AUTOSAR XML (schema 4-0-3)
package /CalibrationComponents
  parameter sw component type VSDR: data-type-mapping=[VSDR_CodeDataTypeMappingsSet, WorkingDataTypeMappingsSet]
    provide port VSDR_Pport: provided-interface=VSDR_if
      provided-com-specs:
        init-value=VSDR_Pport_KaVSDR_I_OvrdValue_HallSensorCalOffSet:[0, 0], parameter=KaVSDR_I_OvrdValue_HallSensorCalOffSet
        init-value=15, parameter=KeVSDR_Cnt_MaxSamplesForCurrOffset
        init-value=380, parameter=KeVSDR_I_HVOverCurrentThresh
        init-value=73, parameter=KeVSDR_I_HallBoundaryLarge
        init-value=76, parameter=KeVSDR_I_HallBoundaryLargeCritical
        init-value=74, parameter=KeVSDR_I_HallBoundarySmall
        init-value=530, parameter=KeVSDR_I_HallCurrent_MaxVal
        init-value=-530, parameter=KeVSDR_I_HallCurrent_minVal
        init-value=4, parameter=KeVSDR_I_HallLargeVolatility
        init-value=0.4000000059604645, parameter=KeVSDR_I_HallSmallVolatility
        init-value=0, parameter=KeVSDR_I_NegCurrentThreshold
        init-value=0, parameter=KeVSDR_I_OffsetCurrCAB500Val
        init-value=0, parameter=KeVSDR_I_OvrdValue_HallCurrent
        init-value=0, parameter=KeVSDR_I_OvrdValue_HallCurrentUnfiltered
        init-value=0, parameter=KeVSDR_I_OvrdValue_HallCurrent_Vehicle
        init-value=3, parameter=KeVSDR_I_PlausibilityThrshCAB500
        init-value=3, parameter=KeVSDR_I_PlausibilityThrshCAB500High
        init-value=-3, parameter=KeVSDR_I_PlausibilityThrshCAB500Low
        init-value=1, parameter=KeVSDR_I_PlausibilityThrshHallSnsCh1
        init-value=3, parameter=KeVSDR_I_PlausibilityThrshHallSnsCh2
        init-value=0, parameter=KeVSDR_I_PosCurrentThreshold
        init-value=390, parameter=KeVSDR_U_OvrdValBusVoltage
        init-value=0, parameter=KeVSDR_U_OvrdValue_HighVoltage
        init-value=20, parameter=KeVSDR_U_ThrshldDiffVoltPackVmcur
        init-value=15, parameter=KeVSDR_U_ThrshldDiffVoltPackVmcur_Pass
        init-value=20, parameter=KeVSDR_U_ThrshldDiffVoltSumCellLink
        init-value=15, parameter=KeVSDR_U_ThrshldDiffVoltSumCellLink_Pass
        init-value=20, parameter=KeVSDR_U_ThrshldDiffVoltSumCellPack
        init-value=15, parameter=KeVSDR_U_ThrshldDiffVoltSumCellPack_Pass
        init-value=1, parameter=KeVSDR_k_HallLargeFilterSecondD
        init-value=0.8999999761581421, parameter=KeVSDR_k_HallLargeFltrCoef
        init-value=1, parameter=KeVSDR_k_HallSmallFilterSecondD
        init-value=0.8999999761581421, parameter=KeVSDR_k_HallSmallFltrCoef
        init-value=0.10000000149011612, parameter=KeVSDR_k_OvrdValue_HallLargeFilter
        init-value=0.10000000149011612, parameter=KeVSDR_k_OvrdValue_HallSmallFilter
        init-value=0, parameter=KeVSDR_q_AccuChgCoulombs_Val
        init-value=0, parameter=KeVSDR_q_OvrdValue_AccuCoulombs
        init-value=0.05000000074505806, parameter=KeVSDR_t_DbncCurrentCloseToZero
        init-value=0.05000000074505806, parameter=KeVSDR_t_DbncCurrentGreaterThanZero
        init-value=0.05000000074505806, parameter=KeVSDR_t_DbncCurrentLessThanZero
        init-value=0.20000000298023224, parameter=KeVSDR_t_DbncHVOverCurrent_flt
        init-value=4, parameter=KeVSDR_t_DbncLinkVoltageInRange_flt
        init-value=4, parameter=KeVSDR_t_DbncPackVoltageInRange_flt
        init-value=0.20000000298023224, parameter=KeVSDR_t_Debc_HallBadSignalLarge
        init-value=0.20000000298023224, parameter=KeVSDR_t_Debc_HallBadSignalSmall
        init-value=0.10000000149011612, parameter=KeVSDR_t_Debc_HallBoundaryLargeDown
        init-value=0.10000000149011612, parameter=KeVSDR_t_Debc_HallBoundaryLargeUp
        init-value=10, parameter=KeVSDR_t_Debc_HallBoundarySmall
        init-value=0.10000000149011612, parameter=KeVSDR_t_Debc_HallBoundarySmallDown
        init-value=0.10000000149011612, parameter=KeVSDR_t_Debc_HallBoundarySmallUp
        init-value=0.009999999776482582, parameter=KeVSDR_t_HallLargeFilterSecondT
        init-value=0.009999999776482582, parameter=KeVSDR_t_HallSmallFilterSecondT
        init-value=0.009999999776482582, parameter=KeVSDR_t_SR_VSDR
        init-value=4, parameter=KeVSDR_Cnt_HallBoundarySmall
        init-value=CeHVSR_e_StateModeStandBy, parameter=KeVSDR_e_StateModeStandBy
        init-value=CeVSDR_e_CurFlowStateInit, parameter=KeVSDR_e_CurrentFlowStateOvrdVal
        init-value=0, parameter=KeVSDR_b_AccuChgCoulombs_Ctrl
        init-value=0, parameter=KeVSDR_b_CurrSnsCAB500Plausibilty_flt_Ctrl
        init-value=0, parameter=KeVSDR_b_CurrentFlowStateOvrdCtrl
        init-value=1, parameter=KeVSDR_b_HallSignal12
        init-value=0, parameter=KeVSDR_b_HallSnsPlausibiltyCh1FaultOrvd
        init-value=1, parameter=KeVSDR_b_HallSnsPlausibiltyCh1FaultOrvdCtrl
        init-value=0, parameter=KeVSDR_b_HallSnsPlausibiltyCh2FaultOrvd
        init-value=1, parameter=KeVSDR_b_HallSnsPlausibiltyCh2FaultOrvdCtrl
        init-value=0, parameter=KeVSDR_b_LinkVoltageInRange_flt_Ctrl
        init-value=0, parameter=KeVSDR_b_OffsetCurrCAB500Ctrl
        init-value=0, parameter=KeVSDR_b_OvrdCond_AccuCoulombs
        init-value=0, parameter=KeVSDR_b_OvrdCond_HallCurrent
        init-value=0, parameter=KeVSDR_b_OvrdCond_HallCurrentUnfiltered
        init-value=0, parameter=KeVSDR_b_OvrdCond_HallCurrent_Vehicle
        init-value=1, parameter=KeVSDR_b_OvrdCond_HallLargeFilter
        init-value=1, parameter=KeVSDR_b_OvrdCond_HallSensorCalOffSet
        init-value=1, parameter=KeVSDR_b_OvrdCond_HallSmallFilter
        init-value=0, parameter=KeVSDR_b_OvrdCond_HighVoltage
        init-value=0, parameter=KeVSDR_b_OvrdCtrlBusVoltage
        init-value=0, parameter=KeVSDR_b_PackVoltageInRange_flt_Ctrl
        init-value=0, parameter=KeVSDR_k_CurrSnsCAB500Plausibilty_flt_Val
        init-value=0, parameter=KeVSDR_k_LinkVoltageInRange_flt_Val
        init-value=0, parameter=KeVSDR_k_PackVoltageInRange_flt_Val
        init-value=2, parameter=KeVSDR_k_SnsTypeCAB500
        init-value=1, parameter=KeVSDR_k_SnsTypeDHAB_S124
package /VSDR_Code_pkg/VSDR_Code_swc
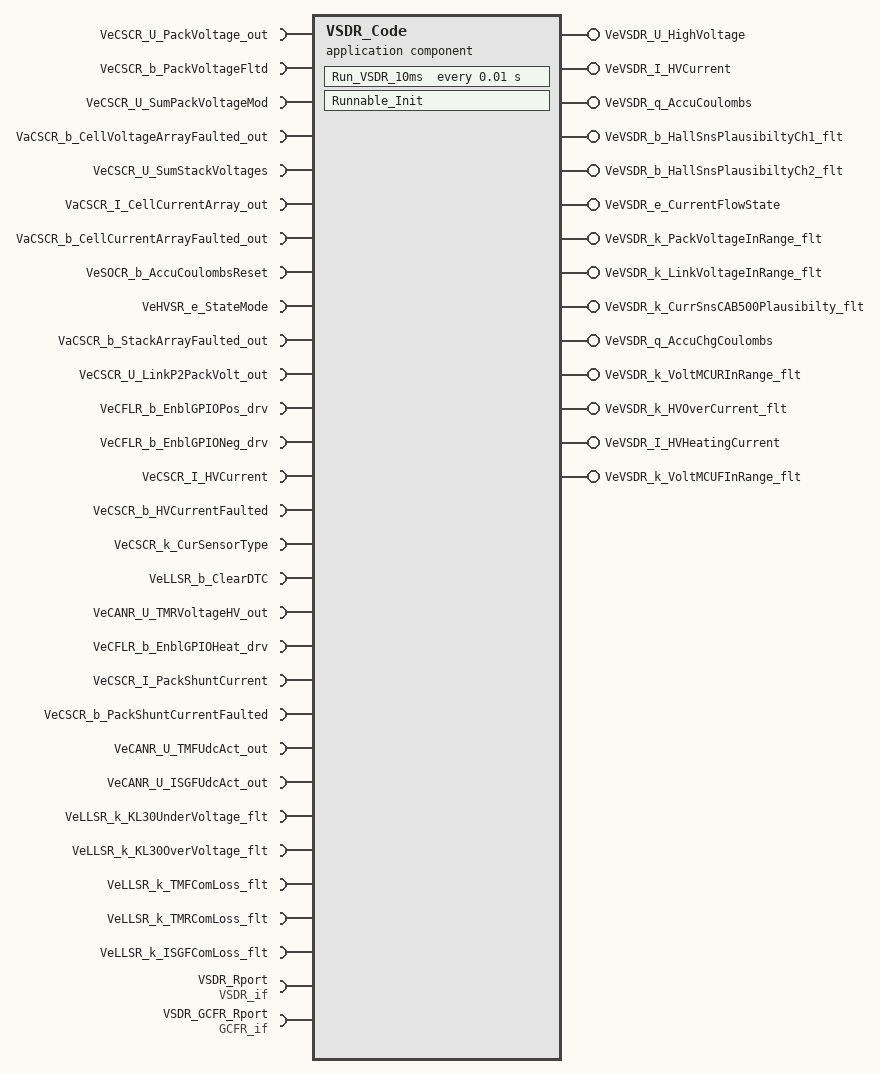
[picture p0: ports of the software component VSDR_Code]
  application sw component type VSDR_Code
    28 x require port:
      VeCSCR_U_PackVoltage_out: nonqueued-receiver-com-spec{data-element=VeCSCR_U_PackVoltage_out, init-value=0}, required-interface=VeCSCR_U_PackVoltage_out
      VeCSCR_b_PackVoltageFltd: nonqueued-receiver-com-spec{data-element=VeCSCR_b_PackVoltageFltd, init-value=0}, required-interface=VeCSCR_b_PackVoltageFltd
      VeCSCR_U_SumPackVoltageMod: nonqueued-receiver-com-spec{data-element=VeCSCR_U_SumPackVoltageMod, init-value=0}, required-interface=VeCSCR_U_SumPackVoltageMod
      VaCSCR_b_CellVoltageArrayFaulted_out: nonqueued-receiver-com-spec{data-element=VaCSCR_b_CellVoltageArrayFaulted_out, init-value=96 x 0}, required-interface=VaCSCR_b_CellVoltageArrayFaulted_out
      VeCSCR_U_SumStackVoltages: nonqueued-receiver-com-spec{data-element=VeCSCR_U_SumStackVoltages, init-value=0}, required-interface=VeCSCR_U_SumStackVoltages
      VaCSCR_I_CellCurrentArray_out: nonqueued-receiver-com-spec{data-element=VaCSCR_I_CellCurrentArray_out, init-value=[0, 0]}, required-interface=VaCSCR_I_CellCurrentArray_out
      VaCSCR_b_CellCurrentArrayFaulted_out: nonqueued-receiver-com-spec{data-element=VaCSCR_b_CellCurrentArrayFaulted_out, init-value=[0, 0]}, required-interface=VaCSCR_b_CellCurrentArrayFaulted_out
      VeSOCR_b_AccuCoulombsReset: nonqueued-receiver-com-spec{data-element=VeSOCR_b_AccuCoulombsReset, init-value=0}, required-interface=VeSOCR_b_AccuCoulombsReset
      VeHVSR_e_StateMode: nonqueued-receiver-com-spec{data-element=VeHVSR_e_StateMode, init-value=CeHVSR_e_StateModeReserved}, required-interface=VeHVSR_e_StateMode
      VaCSCR_b_StackArrayFaulted_out: nonqueued-receiver-com-spec{data-element=VaCSCR_b_StackArrayFaulted_out, init-value=8 x 0}, required-interface=VaCSCR_b_StackArrayFaulted_out
      VeCSCR_U_LinkP2PackVolt_out: nonqueued-receiver-com-spec{data-element=VeCSCR_U_LinkP2PackVolt_out, init-value=0}, required-interface=VeCSCR_U_LinkP2PackVolt_out
      VeCFLR_b_EnblGPIOPos_drv: nonqueued-receiver-com-spec{data-element=VeCFLR_b_EnblGPIOPos_drv, init-value=0}, required-interface=VeCFLR_b_EnblGPIOPos_drv
      VeCFLR_b_EnblGPIONeg_drv: nonqueued-receiver-com-spec{data-element=VeCFLR_b_EnblGPIONeg_drv, init-value=0}, required-interface=VeCFLR_b_EnblGPIONeg_drv
      VeCSCR_I_HVCurrent: nonqueued-receiver-com-spec{data-element=VeCSCR_I_HVCurrent, init-value=0}, required-interface=VeCSCR_I_HVCurrent
      VeCSCR_b_HVCurrentFaulted: nonqueued-receiver-com-spec{data-element=VeCSCR_b_HVCurrentFaulted, init-value=0}, required-interface=VeCSCR_b_HVCurrentFaulted
      VeCSCR_k_CurSensorType: nonqueued-receiver-com-spec{data-element=VeCSCR_k_CurSensorType, init-value=0}, required-interface=VeCSCR_k_CurSensorType
      VeLLSR_b_ClearDTC: nonqueued-receiver-com-spec{data-element=VeLLSR_b_ClearDTC, init-value=0}, required-interface=VeLLSR_b_ClearDTC
      VeCANR_U_TMRVoltageHV_out: nonqueued-receiver-com-spec{data-element=VeCANR_U_TMRVoltageHV_out, init-value=0}, required-interface=VeCANR_U_TMRVoltageHV_out
      VeCFLR_b_EnblGPIOHeat_drv: nonqueued-receiver-com-spec{data-element=VeCFLR_b_EnblGPIOHeat_drv, init-value=0}, required-interface=VeCFLR_b_EnblGPIOHeat_drv
      VeCSCR_I_PackShuntCurrent: nonqueued-receiver-com-spec{data-element=VeCSCR_I_PackShuntCurrent, init-value=0}, required-interface=VeCSCR_I_PackShuntCurrent
      VeCSCR_b_PackShuntCurrentFaulted: nonqueued-receiver-com-spec{data-element=VeCSCR_b_PackShuntCurrentFaulted, init-value=0}, required-interface=VeCSCR_b_PackShuntCurrentFaulted
      VeCANR_U_TMFUdcAct_out: nonqueued-receiver-com-spec{data-element=VeCANR_U_TMFUdcAct_out, init-value=0}, required-interface=VeCANR_U_TMFUdcAct_out
      VeCANR_U_ISGFUdcAct_out: nonqueued-receiver-com-spec{data-element=VeCANR_U_ISGFUdcAct_out, init-value=0}, required-interface=VeCANR_U_ISGFUdcAct_out
      VeLLSR_k_KL30UnderVoltage_flt: nonqueued-receiver-com-spec{data-element=VeLLSR_k_KL30UnderVoltage_flt, init-value=0}, required-interface=VeLLSR_k_KL30UnderVoltage_flt
      VeLLSR_k_KL30OverVoltage_flt: nonqueued-receiver-com-spec{data-element=VeLLSR_k_KL30OverVoltage_flt, init-value=0}, required-interface=VeLLSR_k_KL30OverVoltage_flt
      VeLLSR_k_TMFComLoss_flt: nonqueued-receiver-com-spec{data-element=VeLLSR_k_TMFComLoss_flt, init-value=0}, required-interface=VeLLSR_k_TMFComLoss_flt
      VeLLSR_k_TMRComLoss_flt: nonqueued-receiver-com-spec{data-element=VeLLSR_k_TMRComLoss_flt, init-value=0}, required-interface=VeLLSR_k_TMRComLoss_flt
      VeLLSR_k_ISGFComLoss_flt: nonqueued-receiver-com-spec{data-element=VeLLSR_k_ISGFComLoss_flt, init-value=0}, required-interface=VeLLSR_k_ISGFComLoss_flt
    14 x provide port:
      VeVSDR_U_HighVoltage: nonqueued-sender-com-spec{data-element=VeVSDR_U_HighVoltage, init-value=0}, provided-interface=VeVSDR_U_HighVoltage
      VeVSDR_I_HVCurrent: nonqueued-sender-com-spec{data-element=VeVSDR_I_HVCurrent, init-value=0}, provided-interface=VeVSDR_I_HVCurrent
      VeVSDR_q_AccuCoulombs: nonqueued-sender-com-spec{data-element=VeVSDR_q_AccuCoulombs, init-value=0}, provided-interface=VeVSDR_q_AccuCoulombs
      VeVSDR_b_HallSnsPlausibiltyCh1_flt: nonqueued-sender-com-spec{data-element=VeVSDR_b_HallSnsPlausibiltyCh1_flt, init-value=0}, provided-interface=VeVSDR_b_HallSnsPlausibiltyCh1_flt
      VeVSDR_b_HallSnsPlausibiltyCh2_flt: nonqueued-sender-com-spec{data-element=VeVSDR_b_HallSnsPlausibiltyCh2_flt, init-value=0}, provided-interface=VeVSDR_b_HallSnsPlausibiltyCh2_flt
      VeVSDR_e_CurrentFlowState: nonqueued-sender-com-spec{data-element=VeVSDR_e_CurrentFlowState, init-value=CeVSDR_e_CurFlowStateInit}, provided-interface=VeVSDR_e_CurrentFlowState
      VeVSDR_k_PackVoltageInRange_flt: nonqueued-sender-com-spec{data-element=VeVSDR_k_PackVoltageInRange_flt, init-value=0}, provided-interface=VeVSDR_k_PackVoltageInRange_flt
      VeVSDR_k_LinkVoltageInRange_flt: nonqueued-sender-com-spec{data-element=VeVSDR_k_LinkVoltageInRange_flt, init-value=0}, provided-interface=VeVSDR_k_LinkVoltageInRange_flt
      VeVSDR_k_CurrSnsCAB500Plausibilty_flt: nonqueued-sender-com-spec{data-element=VeVSDR_k_CurrSnsCAB500Plausibilty_flt, init-value=0}, provided-interface=VeVSDR_k_CurrSnsCAB500Plausibilty_flt
      VeVSDR_q_AccuChgCoulombs: nonqueued-sender-com-spec{data-element=VeVSDR_q_AccuChgCoulombs, init-value=0}, provided-interface=VeVSDR_q_AccuChgCoulombs
      VeVSDR_k_VoltMCURInRange_flt: nonqueued-sender-com-spec{data-element=VeVSDR_k_VoltMCURInRange_flt, init-value=0}, provided-interface=VeVSDR_k_VoltMCURInRange_flt
      VeVSDR_k_HVOverCurrent_flt: nonqueued-sender-com-spec{data-element=VeVSDR_k_HVOverCurrent_flt, init-value=0}, provided-interface=VeVSDR_k_HVOverCurrent_flt
      VeVSDR_I_HVHeatingCurrent: nonqueued-sender-com-spec{data-element=VeVSDR_I_HVHeatingCurrent, init-value=0}, provided-interface=VeVSDR_I_HVHeatingCurrent
      VeVSDR_k_VoltMCUFInRange_flt: nonqueued-sender-com-spec{data-element=VeVSDR_k_VoltMCUFInRange_flt, init-value=0}, provided-interface=VeVSDR_k_VoltMCUFInRange_flt
    require port VSDR_Rport: required-interface=VSDR_if
    require port VSDR_GCFR_Rport: required-interface=GCFR_if
    behavior VSDR_Code: constant-value-mapping=VSDR_Code_datatype_AVS_MappingSet, data-type-mapping=[VSDR_CodeDataTypeMappingsSet, WorkingDataTypeMappingsSet], handle-termination-and-restart=NO-SUPPORT
      timing event Event_Run_VSDR_10ms: start-on-event=Run_VSDR_10ms, period=0.01
      runnable Runnable_Init: symbol=VSDR_Code_Init
      runnable Run_VSDR_10ms
        data-read-access:
          28 x access:
            IN_VaCSCR_I_CellCurrentArray_out_VaCSCR_I_CellCurrentArray_out: accessed-variable=VaCSCR_I_CellCurrentArray_out.VaCSCR_I_CellCurrentArray_out
            IN_VaCSCR_b_CellCurrentArrayFaulted_out_VaCSC_3e50cb7ef47845b0: accessed-variable=VaCSCR_b_CellCurrentArrayFaulted_out.VaCSCR_b_CellCurrentArrayFaulted_out
            IN_VaCSCR_b_CellVoltageArrayFaulted_out_VaCSC_69038eed315e24cb: accessed-variable=VaCSCR_b_CellVoltageArrayFaulted_out.VaCSCR_b_CellVoltageArrayFaulted_out
            IN_VaCSCR_b_StackArrayFaulted_out_VaCSCR_b_St_5f0f7fadf9742ff2: accessed-variable=VaCSCR_b_StackArrayFaulted_out.VaCSCR_b_StackArrayFaulted_out
            IN_VeCANR_U_ISGFUdcAct_out_VeCANR_U_ISGFUdcAct_out: accessed-variable=VeCANR_U_ISGFUdcAct_out.VeCANR_U_ISGFUdcAct_out
            IN_VeCANR_U_TMFUdcAct_out_VeCANR_U_TMFUdcAct_out: accessed-variable=VeCANR_U_TMFUdcAct_out.VeCANR_U_TMFUdcAct_out
            IN_VeCANR_U_TMRVoltageHV_out_VeCANR_U_TMRVoltageHV_out: accessed-variable=VeCANR_U_TMRVoltageHV_out.VeCANR_U_TMRVoltageHV_out
            IN_VeCFLR_b_EnblGPIOHeat_drv_VeCFLR_b_EnblGPIOHeat_drv: accessed-variable=VeCFLR_b_EnblGPIOHeat_drv.VeCFLR_b_EnblGPIOHeat_drv
            IN_VeCFLR_b_EnblGPIONeg_drv_VeCFLR_b_EnblGPIONeg_drv: accessed-variable=VeCFLR_b_EnblGPIONeg_drv.VeCFLR_b_EnblGPIONeg_drv
            IN_VeCFLR_b_EnblGPIOPos_drv_VeCFLR_b_EnblGPIOPos_drv: accessed-variable=VeCFLR_b_EnblGPIOPos_drv.VeCFLR_b_EnblGPIOPos_drv
            IN_VeCSCR_I_HVCurrent_VeCSCR_I_HVCurrent: accessed-variable=VeCSCR_I_HVCurrent.VeCSCR_I_HVCurrent
            IN_VeCSCR_I_PackShuntCurrent_VeCSCR_I_PackShuntCurrent: accessed-variable=VeCSCR_I_PackShuntCurrent.VeCSCR_I_PackShuntCurrent
            IN_VeCSCR_U_LinkP2PackVolt_out_VeCSCR_U_LinkP2PackVolt_out: accessed-variable=VeCSCR_U_LinkP2PackVolt_out.VeCSCR_U_LinkP2PackVolt_out
            IN_VeCSCR_U_PackVoltage_out_VeCSCR_U_PackVoltage_out: accessed-variable=VeCSCR_U_PackVoltage_out.VeCSCR_U_PackVoltage_out
            IN_VeCSCR_U_SumPackVoltageMod_VeCSCR_U_SumPackVoltageMod: accessed-variable=VeCSCR_U_SumPackVoltageMod.VeCSCR_U_SumPackVoltageMod
            IN_VeCSCR_U_SumStackVoltages_VeCSCR_U_SumStackVoltages: accessed-variable=VeCSCR_U_SumStackVoltages.VeCSCR_U_SumStackVoltages
            IN_VeCSCR_b_HVCurrentFaulted_VeCSCR_b_HVCurrentFaulted: accessed-variable=VeCSCR_b_HVCurrentFaulted.VeCSCR_b_HVCurrentFaulted
            IN_VeCSCR_b_PackShuntCurrentFaulted_VeCSCR_b_d5cd9cda5268a3a3: accessed-variable=VeCSCR_b_PackShuntCurrentFaulted.VeCSCR_b_PackShuntCurrentFaulted
            IN_VeCSCR_b_PackVoltageFltd_VeCSCR_b_PackVoltageFltd: accessed-variable=VeCSCR_b_PackVoltageFltd.VeCSCR_b_PackVoltageFltd
            IN_VeCSCR_k_CurSensorType_VeCSCR_k_CurSensorType: accessed-variable=VeCSCR_k_CurSensorType.VeCSCR_k_CurSensorType
            IN_VeHVSR_e_StateMode_VeHVSR_e_StateMode: accessed-variable=VeHVSR_e_StateMode.VeHVSR_e_StateMode
            IN_VeLLSR_b_ClearDTC_VeLLSR_b_ClearDTC: accessed-variable=VeLLSR_b_ClearDTC.VeLLSR_b_ClearDTC
            IN_VeLLSR_k_ISGFComLoss_flt_VeLLSR_k_ISGFComLoss_flt: accessed-variable=VeLLSR_k_ISGFComLoss_flt.VeLLSR_k_ISGFComLoss_flt
            IN_VeLLSR_k_KL30OverVoltage_flt_VeLLSR_k_KL30OverVoltage_flt: accessed-variable=VeLLSR_k_KL30OverVoltage_flt.VeLLSR_k_KL30OverVoltage_flt
            IN_VeLLSR_k_KL30UnderVoltage_flt_VeLLSR_k_KL30UnderVoltage_flt: accessed-variable=VeLLSR_k_KL30UnderVoltage_flt.VeLLSR_k_KL30UnderVoltage_flt
            IN_VeLLSR_k_TMFComLoss_flt_VeLLSR_k_TMFComLoss_flt: accessed-variable=VeLLSR_k_TMFComLoss_flt.VeLLSR_k_TMFComLoss_flt
            IN_VeLLSR_k_TMRComLoss_flt_VeLLSR_k_TMRComLoss_flt: accessed-variable=VeLLSR_k_TMRComLoss_flt.VeLLSR_k_TMRComLoss_flt
            IN_VeSOCR_b_AccuCoulombsReset_VeSOCR_b_AccuCoulombsReset: accessed-variable=VeSOCR_b_AccuCoulombsReset.VeSOCR_b_AccuCoulombsReset
        data-send-points:
          14 x access:
            OUT_VeVSDR_U_HighVoltage_VeVSDR_U_HighVoltage: accessed-variable=VeVSDR_U_HighVoltage.VeVSDR_U_HighVoltage
            OUT_VeVSDR_I_HVCurrent_VeVSDR_I_HVCurrent: accessed-variable=VeVSDR_I_HVCurrent.VeVSDR_I_HVCurrent
            OUT_VeVSDR_q_AccuCoulombs_VeVSDR_q_AccuCoulombs: accessed-variable=VeVSDR_q_AccuCoulombs.VeVSDR_q_AccuCoulombs
            OUT_VeVSDR_b_HallSnsPlausibiltyCh1_flt_VeVSDR_11a93c6d08f6d2c0: accessed-variable=VeVSDR_b_HallSnsPlausibiltyCh1_flt.VeVSDR_b_HallSnsPlausibiltyCh1_flt
            OUT_VeVSDR_b_HallSnsPlausibiltyCh2_flt_VeVSDR_f4757b826f463550: accessed-variable=VeVSDR_b_HallSnsPlausibiltyCh2_flt.VeVSDR_b_HallSnsPlausibiltyCh2_flt
            OUT_VeVSDR_e_CurrentFlowState_VeVSDR_e_CurrentFlowState: accessed-variable=VeVSDR_e_CurrentFlowState.VeVSDR_e_CurrentFlowState
            OUT_VeVSDR_k_PackVoltageInRange_flt_VeVSDR_k_a8f074a2e6c4a404: accessed-variable=VeVSDR_k_PackVoltageInRange_flt.VeVSDR_k_PackVoltageInRange_flt
            OUT_VeVSDR_k_LinkVoltageInRange_flt_VeVSDR_k_fec0781f02144831: accessed-variable=VeVSDR_k_LinkVoltageInRange_flt.VeVSDR_k_LinkVoltageInRange_flt
            OUT_VeVSDR_k_CurrSnsCAB500Plausibilty_flt_VeV_71082944fa98999b: accessed-variable=VeVSDR_k_CurrSnsCAB500Plausibilty_flt.VeVSDR_k_CurrSnsCAB500Plausibilty_flt
            OUT_VeVSDR_q_AccuChgCoulombs_VeVSDR_q_AccuChgCoulombs: accessed-variable=VeVSDR_q_AccuChgCoulombs.VeVSDR_q_AccuChgCoulombs
            OUT_VeVSDR_k_VoltMCURInRange_flt_VeVSDR_k_VoltMCURInRange_flt: accessed-variable=VeVSDR_k_VoltMCURInRange_flt.VeVSDR_k_VoltMCURInRange_flt
            OUT_VeVSDR_k_HVOverCurrent_flt_VeVSDR_k_HVOverCurrent_flt: accessed-variable=VeVSDR_k_HVOverCurrent_flt.VeVSDR_k_HVOverCurrent_flt
            OUT_VeVSDR_I_HVHeatingCurrent_VeVSDR_I_HVHeatingCurrent: accessed-variable=VeVSDR_I_HVHeatingCurrent.VeVSDR_I_HVHeatingCurrent
            OUT_VeVSDR_k_VoltMCUFInRange_flt_VeVSDR_k_VoltMCUFInRange_flt: accessed-variable=VeVSDR_k_VoltMCUFInRange_flt.VeVSDR_k_VoltMCUFInRange_flt
        87 x parameter access:
          CALPRM_VSDR_Rport_KaVSDR_I_OvrdValue_HallSensorCalOffSet: accessed-parameter=VSDR_Rport.KaVSDR_I_OvrdValue_HallSensorCalOffSet
          CALPRM_VSDR_GCFR_Rport_KeGCFR_Cnt_NumberOfCSC: accessed-parameter=VSDR_GCFR_Rport.KeGCFR_Cnt_NumberOfCSC
          CALPRM_VSDR_GCFR_Rport_KeGCFR_Cnt_NumberofCells: accessed-parameter=VSDR_GCFR_Rport.KeGCFR_Cnt_NumberofCells
          CALPRM_VSDR_Rport_KeVSDR_Cnt_HallBoundarySmall: accessed-parameter=VSDR_Rport.KeVSDR_Cnt_HallBoundarySmall
          CALPRM_VSDR_Rport_KeVSDR_Cnt_MaxSamplesForCurrOffset: accessed-parameter=VSDR_Rport.KeVSDR_Cnt_MaxSamplesForCurrOffset
          CALPRM_VSDR_Rport_KeVSDR_I_HVOverCurrentThresh: accessed-parameter=VSDR_Rport.KeVSDR_I_HVOverCurrentThresh
          CALPRM_VSDR_Rport_KeVSDR_I_HallBoundaryLarge: accessed-parameter=VSDR_Rport.KeVSDR_I_HallBoundaryLarge
          CALPRM_VSDR_Rport_KeVSDR_I_HallBoundaryLargeCritical: accessed-parameter=VSDR_Rport.KeVSDR_I_HallBoundaryLargeCritical
          CALPRM_VSDR_Rport_KeVSDR_I_HallBoundarySmall: accessed-parameter=VSDR_Rport.KeVSDR_I_HallBoundarySmall
          CALPRM_VSDR_Rport_KeVSDR_I_HallCurrent_MaxVal: accessed-parameter=VSDR_Rport.KeVSDR_I_HallCurrent_MaxVal
          CALPRM_VSDR_Rport_KeVSDR_I_HallCurrent_minVal: accessed-parameter=VSDR_Rport.KeVSDR_I_HallCurrent_minVal
          CALPRM_VSDR_Rport_KeVSDR_I_HallLargeVolatility: accessed-parameter=VSDR_Rport.KeVSDR_I_HallLargeVolatility
          CALPRM_VSDR_Rport_KeVSDR_I_HallSmallVolatility: accessed-parameter=VSDR_Rport.KeVSDR_I_HallSmallVolatility
          CALPRM_VSDR_Rport_KeVSDR_I_NegCurrentThreshold: accessed-parameter=VSDR_Rport.KeVSDR_I_NegCurrentThreshold
          CALPRM_VSDR_Rport_KeVSDR_I_OffsetCurrCAB500Val: accessed-parameter=VSDR_Rport.KeVSDR_I_OffsetCurrCAB500Val
          CALPRM_VSDR_Rport_KeVSDR_I_OvrdValue_HallCurrent: accessed-parameter=VSDR_Rport.KeVSDR_I_OvrdValue_HallCurrent
          CALPRM_VSDR_Rport_KeVSDR_I_OvrdValue_HallCurrentUnfiltered: accessed-parameter=VSDR_Rport.KeVSDR_I_OvrdValue_HallCurrentUnfiltered
          CALPRM_VSDR_Rport_KeVSDR_I_OvrdValue_HallCurrent_Vehicle: accessed-parameter=VSDR_Rport.KeVSDR_I_OvrdValue_HallCurrent_Vehicle
          CALPRM_VSDR_Rport_KeVSDR_I_PlausibilityThrshCAB500: accessed-parameter=VSDR_Rport.KeVSDR_I_PlausibilityThrshCAB500
          CALPRM_VSDR_Rport_KeVSDR_I_PlausibilityThrshCAB500High: accessed-parameter=VSDR_Rport.KeVSDR_I_PlausibilityThrshCAB500High
          CALPRM_VSDR_Rport_KeVSDR_I_PlausibilityThrshCAB500Low: accessed-parameter=VSDR_Rport.KeVSDR_I_PlausibilityThrshCAB500Low
          CALPRM_VSDR_Rport_KeVSDR_I_PlausibilityThrshHallSnsCh1: accessed-parameter=VSDR_Rport.KeVSDR_I_PlausibilityThrshHallSnsCh1
          CALPRM_VSDR_Rport_KeVSDR_I_PlausibilityThrshHallSnsCh2: accessed-parameter=VSDR_Rport.KeVSDR_I_PlausibilityThrshHallSnsCh2
          CALPRM_VSDR_Rport_KeVSDR_I_PosCurrentThreshold: accessed-parameter=VSDR_Rport.KeVSDR_I_PosCurrentThreshold
          CALPRM_VSDR_Rport_KeVSDR_U_OvrdValBusVoltage: accessed-parameter=VSDR_Rport.KeVSDR_U_OvrdValBusVoltage
          CALPRM_VSDR_Rport_KeVSDR_U_OvrdValue_HighVoltage: accessed-parameter=VSDR_Rport.KeVSDR_U_OvrdValue_HighVoltage
          CALPRM_VSDR_Rport_KeVSDR_U_ThrshldDiffVoltPackVmcur: accessed-parameter=VSDR_Rport.KeVSDR_U_ThrshldDiffVoltPackVmcur
          CALPRM_VSDR_Rport_KeVSDR_U_ThrshldDiffVoltPackVmcur_Pass: accessed-parameter=VSDR_Rport.KeVSDR_U_ThrshldDiffVoltPackVmcur_Pass
          CALPRM_VSDR_Rport_KeVSDR_U_ThrshldDiffVoltSumCellLink: accessed-parameter=VSDR_Rport.KeVSDR_U_ThrshldDiffVoltSumCellLink
          CALPRM_VSDR_Rport_KeVSDR_U_ThrshldDiffVoltSumCellLink_Pass: accessed-parameter=VSDR_Rport.KeVSDR_U_ThrshldDiffVoltSumCellLink_Pass
          CALPRM_VSDR_Rport_KeVSDR_U_ThrshldDiffVoltSumCellPack: accessed-parameter=VSDR_Rport.KeVSDR_U_ThrshldDiffVoltSumCellPack
          CALPRM_VSDR_Rport_KeVSDR_U_ThrshldDiffVoltSumCellPack_Pass: accessed-parameter=VSDR_Rport.KeVSDR_U_ThrshldDiffVoltSumCellPack_Pass
          CALPRM_VSDR_Rport_KeVSDR_b_AccuChgCoulombs_Ctrl: accessed-parameter=VSDR_Rport.KeVSDR_b_AccuChgCoulombs_Ctrl
          CALPRM_VSDR_Rport_KeVSDR_b_CurrSnsCAB500Plausibilty_flt_Ctrl: accessed-parameter=VSDR_Rport.KeVSDR_b_CurrSnsCAB500Plausibilty_flt_Ctrl
          CALPRM_VSDR_Rport_KeVSDR_b_CurrentFlowStateOvrdCtrl: accessed-parameter=VSDR_Rport.KeVSDR_b_CurrentFlowStateOvrdCtrl
          CALPRM_VSDR_Rport_KeVSDR_b_HallSignal12: accessed-parameter=VSDR_Rport.KeVSDR_b_HallSignal12
          CALPRM_VSDR_Rport_KeVSDR_b_HallSnsPlausibiltyCh1FaultOrvd: accessed-parameter=VSDR_Rport.KeVSDR_b_HallSnsPlausibiltyCh1FaultOrvd
          CALPRM_VSDR_Rport_KeVSDR_b_HallSnsPlausibiltyCh1FaultOrvdCtrl: accessed-parameter=VSDR_Rport.KeVSDR_b_HallSnsPlausibiltyCh1FaultOrvdCtrl
          CALPRM_VSDR_Rport_KeVSDR_b_HallSnsPlausibiltyCh2FaultOrvd: accessed-parameter=VSDR_Rport.KeVSDR_b_HallSnsPlausibiltyCh2FaultOrvd
          CALPRM_VSDR_Rport_KeVSDR_b_HallSnsPlausibiltyCh2FaultOrvdCtrl: accessed-parameter=VSDR_Rport.KeVSDR_b_HallSnsPlausibiltyCh2FaultOrvdCtrl
          CALPRM_VSDR_Rport_KeVSDR_b_LinkVoltageInRange_flt_Ctrl: accessed-parameter=VSDR_Rport.KeVSDR_b_LinkVoltageInRange_flt_Ctrl
          CALPRM_VSDR_Rport_KeVSDR_b_OffsetCurrCAB500Ctrl: accessed-parameter=VSDR_Rport.KeVSDR_b_OffsetCurrCAB500Ctrl
          CALPRM_VSDR_Rport_KeVSDR_b_OvrdCond_AccuCoulombs: accessed-parameter=VSDR_Rport.KeVSDR_b_OvrdCond_AccuCoulombs
          CALPRM_VSDR_Rport_KeVSDR_b_OvrdCond_HallCurrent: accessed-parameter=VSDR_Rport.KeVSDR_b_OvrdCond_HallCurrent
          CALPRM_VSDR_Rport_KeVSDR_b_OvrdCond_HallCurrentUnfiltered: accessed-parameter=VSDR_Rport.KeVSDR_b_OvrdCond_HallCurrentUnfiltered
          CALPRM_VSDR_Rport_KeVSDR_b_OvrdCond_HallCurrent_Vehicle: accessed-parameter=VSDR_Rport.KeVSDR_b_OvrdCond_HallCurrent_Vehicle
          CALPRM_VSDR_Rport_KeVSDR_b_OvrdCond_HallLargeFilter: accessed-parameter=VSDR_Rport.KeVSDR_b_OvrdCond_HallLargeFilter
          CALPRM_VSDR_Rport_KeVSDR_b_OvrdCond_HallSensorCalOffSet: accessed-parameter=VSDR_Rport.KeVSDR_b_OvrdCond_HallSensorCalOffSet
          CALPRM_VSDR_Rport_KeVSDR_b_OvrdCond_HallSmallFilter: accessed-parameter=VSDR_Rport.KeVSDR_b_OvrdCond_HallSmallFilter
          CALPRM_VSDR_Rport_KeVSDR_b_OvrdCond_HighVoltage: accessed-parameter=VSDR_Rport.KeVSDR_b_OvrdCond_HighVoltage
          CALPRM_VSDR_Rport_KeVSDR_b_OvrdCtrlBusVoltage: accessed-parameter=VSDR_Rport.KeVSDR_b_OvrdCtrlBusVoltage
          CALPRM_VSDR_Rport_KeVSDR_b_PackVoltageInRange_flt_Ctrl: accessed-parameter=VSDR_Rport.KeVSDR_b_PackVoltageInRange_flt_Ctrl
          CALPRM_VSDR_Rport_KeVSDR_e_CurrentFlowStateOvrdVal: accessed-parameter=VSDR_Rport.KeVSDR_e_CurrentFlowStateOvrdVal
          CALPRM_VSDR_Rport_KeVSDR_e_StateModeStandBy: accessed-parameter=VSDR_Rport.KeVSDR_e_StateModeStandBy
          CALPRM_VSDR_Rport_KeVSDR_k_CurrSnsCAB500Plausibilty_flt_Val: accessed-parameter=VSDR_Rport.KeVSDR_k_CurrSnsCAB500Plausibilty_flt_Val
          CALPRM_VSDR_Rport_KeVSDR_k_HallLargeFilterSecondD: accessed-parameter=VSDR_Rport.KeVSDR_k_HallLargeFilterSecondD
          CALPRM_VSDR_Rport_KeVSDR_k_HallLargeFltrCoef: accessed-parameter=VSDR_Rport.KeVSDR_k_HallLargeFltrCoef
          CALPRM_VSDR_Rport_KeVSDR_k_HallSmallFilterSecondD: accessed-parameter=VSDR_Rport.KeVSDR_k_HallSmallFilterSecondD
          CALPRM_VSDR_Rport_KeVSDR_k_HallSmallFltrCoef: accessed-parameter=VSDR_Rport.KeVSDR_k_HallSmallFltrCoef
          CALPRM_VSDR_Rport_KeVSDR_k_LinkVoltageInRange_flt_Val: accessed-parameter=VSDR_Rport.KeVSDR_k_LinkVoltageInRange_flt_Val
          CALPRM_VSDR_Rport_KeVSDR_k_OvrdValue_HallLargeFilter: accessed-parameter=VSDR_Rport.KeVSDR_k_OvrdValue_HallLargeFilter
          CALPRM_VSDR_Rport_KeVSDR_k_OvrdValue_HallSmallFilter: accessed-parameter=VSDR_Rport.KeVSDR_k_OvrdValue_HallSmallFilter
          CALPRM_VSDR_Rport_KeVSDR_k_PackVoltageInRange_flt_Val: accessed-parameter=VSDR_Rport.KeVSDR_k_PackVoltageInRange_flt_Val
          CALPRM_VSDR_Rport_KeVSDR_k_SnsTypeCAB500: accessed-parameter=VSDR_Rport.KeVSDR_k_SnsTypeCAB500
          CALPRM_VSDR_Rport_KeVSDR_k_SnsTypeDHAB_S124: accessed-parameter=VSDR_Rport.KeVSDR_k_SnsTypeDHAB_S124
          CALPRM_VSDR_Rport_KeVSDR_q_AccuChgCoulombs_Val: accessed-parameter=VSDR_Rport.KeVSDR_q_AccuChgCoulombs_Val
          CALPRM_VSDR_Rport_KeVSDR_q_OvrdValue_AccuCoulombs: accessed-parameter=VSDR_Rport.KeVSDR_q_OvrdValue_AccuCoulombs
          CALPRM_VSDR_Rport_KeVSDR_t_DbncCurrentCloseToZero: accessed-parameter=VSDR_Rport.KeVSDR_t_DbncCurrentCloseToZero
          CALPRM_VSDR_Rport_KeVSDR_t_DbncCurrentGreaterThanZero: accessed-parameter=VSDR_Rport.KeVSDR_t_DbncCurrentGreaterThanZero
          CALPRM_VSDR_Rport_KeVSDR_t_DbncCurrentLessThanZero: accessed-parameter=VSDR_Rport.KeVSDR_t_DbncCurrentLessThanZero
          CALPRM_VSDR_Rport_KeVSDR_t_DbncHVOverCurrent_flt: accessed-parameter=VSDR_Rport.KeVSDR_t_DbncHVOverCurrent_flt
          CALPRM_VSDR_Rport_KeVSDR_t_DbncLinkVoltageInRange_flt: accessed-parameter=VSDR_Rport.KeVSDR_t_DbncLinkVoltageInRange_flt
          CALPRM_VSDR_Rport_KeVSDR_t_DbncPackVoltageInRange_flt: accessed-parameter=VSDR_Rport.KeVSDR_t_DbncPackVoltageInRange_flt
          CALPRM_VSDR_Rport_KeVSDR_t_Debc_HallBadSignalLarge: accessed-parameter=VSDR_Rport.KeVSDR_t_Debc_HallBadSignalLarge
          CALPRM_VSDR_Rport_KeVSDR_t_Debc_HallBadSignalSmall: accessed-parameter=VSDR_Rport.KeVSDR_t_Debc_HallBadSignalSmall
          CALPRM_VSDR_Rport_KeVSDR_t_Debc_HallBoundaryLargeDown: accessed-parameter=VSDR_Rport.KeVSDR_t_Debc_HallBoundaryLargeDown
          CALPRM_VSDR_Rport_KeVSDR_t_Debc_HallBoundaryLargeUp: accessed-parameter=VSDR_Rport.KeVSDR_t_Debc_HallBoundaryLargeUp
          CALPRM_VSDR_Rport_KeVSDR_t_Debc_HallBoundarySmall: accessed-parameter=VSDR_Rport.KeVSDR_t_Debc_HallBoundarySmall
          CALPRM_VSDR_Rport_KeVSDR_t_Debc_HallBoundarySmallDown: accessed-parameter=VSDR_Rport.KeVSDR_t_Debc_HallBoundarySmallDown
          CALPRM_VSDR_Rport_KeVSDR_t_Debc_HallBoundarySmallUp: accessed-parameter=VSDR_Rport.KeVSDR_t_Debc_HallBoundarySmallUp
          CALPRM_VSDR_Rport_KeVSDR_t_HallLargeFilterSecondT: accessed-parameter=VSDR_Rport.KeVSDR_t_HallLargeFilterSecondT
          CALPRM_VSDR_Rport_KeVSDR_t_HallSmallFilterSecondT: accessed-parameter=VSDR_Rport.KeVSDR_t_HallSmallFilterSecondT
          CALPRM_VSDR_Rport_KeVSDR_t_SR_VSDR: accessed-parameter=VSDR_Rport.KeVSDR_t_SR_VSDR
          SCALPRM_KtVSDR_k_HallLargeFilterCoef_Table: accessed-parameter=KtVSDR_k_HallLargeFilterCoef_Table, sw-calprm-axis-set={sw-axis-index=1, sw-axis-grouped=ar-parameter=KxVSDR_k_HallLargeFilterCoef}
          SCALPRM_KtVSDR_k_HallSmallFilterCoef_Table: accessed-parameter=KtVSDR_k_HallSmallFilterCoef_Table, sw-calprm-axis-set={sw-axis-index=1, sw-axis-grouped=ar-parameter=KxVSDR_k_HallSmallFilterCoef}
          SCALPRM_KxVSDR_k_HallLargeFilterCoef: accessed-parameter=KxVSDR_k_HallLargeFilterCoef
          SCALPRM_KxVSDR_k_HallSmallFilterCoef: accessed-parameter=KxVSDR_k_HallSmallFilterCoef
      shared-parameters:
        4 x parameter data prototype, all with sw-calibration-access=READ-WRITE:
          KtVSDR_k_HallLargeFilterCoef_Table: category=CURVE, type=Appl_KtVSDR_k_HallLargeFilterCoef_Table, init-value=constant-reference={short-label=KtVSDR_k_HallLargeFilterCoef_Table, constant=KtVSDR_k_HallLargeFilterCoef_Table}
          KtVSDR_k_HallSmallFilterCoef_Table: category=CURVE, type=Appl_KtVSDR_k_HallSmallFilterCoef_Table, init-value=constant-reference={short-label=KtVSDR_k_HallSmallFilterCoef_Table, constant=KtVSDR_k_HallSmallFilterCoef_Table}
          KxVSDR_k_HallLargeFilterCoef: category=COM_AXIS, type=Appl_KxVSDR_k_HallLargeFilterCoef, init-value=constant-reference={short-label=KxVSDR_k_HallLargeFilterCoef, constant=KxVSDR_k_HallLargeFilterCoef}
          KxVSDR_k_HallSmallFilterCoef: category=COM_AXIS, type=Appl_KxVSDR_k_HallSmallFilterCoef, init-value=constant-reference={short-label=KxVSDR_k_HallSmallFilterCoef, constant=KxVSDR_k_HallSmallFilterCoef}
